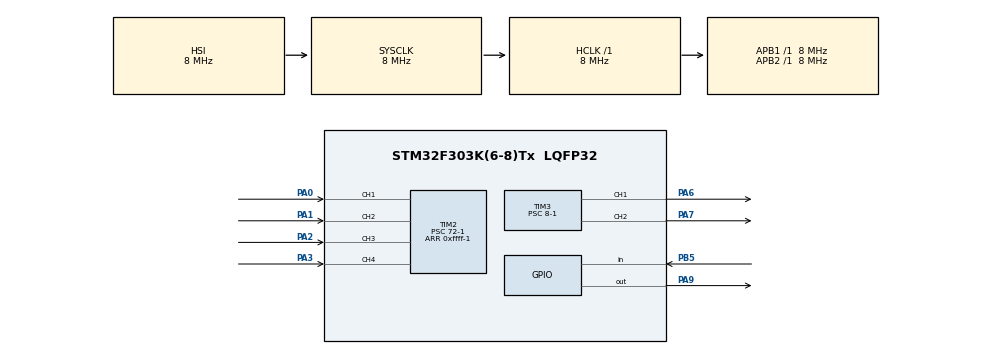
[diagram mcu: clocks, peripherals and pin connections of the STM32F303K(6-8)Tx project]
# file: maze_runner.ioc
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Mcu.Family=STM32F3
Mcu.Name=STM32F303K(6-8)Tx
Mcu.Package=LQFP32
NVIC.PriorityGroup=NVIC_PRIORITYGROUP_4
NVIC.TIM2_IRQn=true\:0\:0\:false\:false\:true\:true\:true\:true
PA0.Signal=S_TIM2_CH1_ETR
PA1.Signal=S_TIM2_CH2
PA2.Signal=S_TIM2_CH3
PA3.Signal=S_TIM2_CH4
PA6.Signal=S_TIM3_CH1
PA7.Signal=S_TIM3_CH2
PA9.Signal=GPIO_Output
PB5.GPIO_PuPd=GPIO_PULLUP
PB5.Signal=GPIO_Input
ProjectManager.HeapSize=0x200
ProjectManager.StackSize=0x400
ProjectManager.TargetToolchain=STM32CubeIDE
RCC.AHBFreq_Value=8000000
RCC.APB1Freq_Value=8000000
RCC.APB2Freq_Value=8000000
RCC.CortexFreq_Value=8000000
RCC.HSE_VALUE=8000000
RCC.HSI_VALUE=8000000
RCC.SYSCLKFreq_VALUE=8000000
SH.S_TIM2_CH1_ETR.0=TIM2_CH1,Input_Capture1_from_TI1
SH.S_TIM2_CH2.0=TIM2_CH2,Input_Capture2_from_TI2
SH.S_TIM2_CH3.0=TIM2_CH3,Input_Capture3_from_TI3
SH.S_TIM2_CH4.0=TIM2_CH4,Input_Capture4_from_TI4
SH.S_TIM3_CH1.0=TIM3_CH1,PWM Generation1 CH1
SH.S_TIM3_CH2.0=TIM3_CH2,PWM Generation2 CH2
TIM2.Channel-Input_Capture1_from_TI1=TIM_CHANNEL_1
TIM2.Channel-Input_Capture2_from_TI2=TIM_CHANNEL_2
TIM2.Channel-Input_Capture3_from_TI3=TIM_CHANNEL_3
TIM2.Channel-Input_Capture4_from_TI4=TIM_CHANNEL_4
TIM2.Period=0xffff-1
TIM2.Prescaler=72-1
TIM3.Channel-PWM\ Generation1\ CH1=TIM_CHANNEL_1
TIM3.Channel-PWM\ Generation2\ CH2=TIM_CHANNEL_2
TIM3.Period=20000-1
TIM3.Prescaler=8-1
TIM3.Pulse-PWM\ Generation1\ CH1=1500-1
TIM3.Pulse-PWM\ Generation2\ CH2=1500-1
VP_TIM3_VS_ClockSourceINT.Mode=Internal
board=custom

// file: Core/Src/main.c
/* USER CODE BEGIN Header */
/**
  ******************************************************************************
  * @file           : main.c
  * @brief          : Main program body
  ******************************************************************************
  * @attention
  *
  * <h2><center>&copy; Copyright (c) 2020 STMicroelectronics.
  * All rights reserved.</center></h2>
  *
  * This software component is licensed by ST under BSD 3-Clause license,
  * the "License"; You may not use this file except in compliance with the
  * License. You may obtain a copy of the License at:
  *                        opensource.org/licenses/BSD-3-Clause
  *
  ******************************************************************************
  */
/* USER CODE END Header */
#include "main.h"
#include "tim.h"
#include "gpio.h"
#include "hcsr04.h"
#include "PCR_servo.h"
#include <stdio.h>
#include <stdlib.h>

int k = 0, before = 0, state = 0;
int i1 = 0, i2 = 0, i3 = 0, i4 = 0;
float d1=1000, d2=1000, d3=1000, d4=1000;
int p1 = 0, p2 = 0, p3 = 0, jp1 = 0, j = 0;

void SystemClock_Config(void);
int validate(int distance, float *sensor, int *current_status, int count);
EDGE_TYPE edgeDetect(uint8_t pin_state, uint8_t samples);

/* USER CODE BEGIN 0 */

// Let's write the callback function

/* USER CODE END 0 */

int main(void)
{

  /* MCU Configuration--------------------------------------------------------*/

  /* Reset of all peripherals, Initializes the Flash interface and the Systick. */
  HAL_Init();

  /* Configure the system clock */
  SystemClock_Config();

  /* Initialize all configured peripherals */
  MX_GPIO_Init();
  MX_TIM3_Init();
  MX_TIM2_Init();
  /* USER CODE BEGIN 2 */
  HAL_TIM_Base_Start(&htim3);
  HAL_TIM_PWM_Start(&htim3, TIM_CHANNEL_1);
  HAL_TIM_PWM_Start(&htim3, TIM_CHANNEL_2);

  HAL_TIM_IC_Start_IT(&htim2, TIM_CHANNEL_1);
  HAL_TIM_IC_Start_IT(&htim2, TIM_CHANNEL_2);
  HAL_TIM_IC_Start_IT(&htim2, TIM_CHANNEL_3);
  HAL_TIM_IC_Start_IT(&htim2, TIM_CHANNEL_4);

  while (1)
  {
	  if (edgeDetect(!HAL_GPIO_ReadPin(GPIOB, GPIO_PIN_5), 3) == RISE) {
		  if (state == 1) state = 0;
	  	  else state = 1;
	      switch (state) {
	      case 1:
	    	  PCR_go_forward();
	    	  break;
	  	  case 0:
	  		  PCR_stand_still();
	  		  break;
	  	  }
	  }
	   before = !HAL_GPIO_ReadPin(GPIOB, GPIO_PIN_5);

	   if (state == 1){
		   j += 1;
		   if (j > 5){
			   j = 0;
			   if (jp1 < 5 && HCSR04_Read2() <= 20){
				   p1 = 0;
				   HAL_Delay(60);
				   if (HCSR04_Read3() > 20){
					   PCR_go_forward();
				   }
				   HAL_Delay(60);
			   } else if (jp1 < 5){
				   p1 = 0;
				   HAL_Delay(60);
				   PCR_go_forward();
			   }
		   }

		   d3 = HCSR04_Read3();

		   if (validate(25, &d3, &i3, 5) == 1){ //front
			   PCR_stand_still();
			   HAL_Delay(60);
			   d1 = HCSR04_Read1();
			   if (validate(20, &d1, &i1, 5) == 1){ //right
				   PCR_stand_still();
				   HAL_Delay(60);
				   d4 = HCSR04_Read4();
				   if (validate(20, &d4, &i4, 5) == 1){ //left
					   PCR_stand_still();
					   HAL_Delay(60);
					   d2 = HCSR04_Read2();
					   if (validate(20, &d2, &i2, 5) == 1){ //back
						   PCR_stand_still();
					   } else{
						   p3 += 1;
					   }
					   if (p3 >= 5){
						   PCR_go_backwards();
						   HAL_Delay(2000);
						   PCR_right_arc(0);
						   HAL_Delay(2000);
						   PCR_go_forward();
						   i1 = 0; i3 = 0; p1 = 0; p2 = 0; p3 = 0; i2 = 0; i4 = 0;
					   } //back end
				   } else{
					   p2 += 1;
				   }
				   if (p2 >= 5){
					   PCR_left_arc(0);
					   HAL_Delay(2000);
					   PCR_go_forward();
					   i1 = 0; i3 = 0; p1 = 0; p2 = 0; p3 = 0; i2 = 0; i4 = 0;
				   } //left end
			   } else{
				   p1 += 1;
			   }
			   if (p1 >= 5){
				   PCR_right_arc(0);
				   HAL_Delay(2000);
				   PCR_go_forward();
				   i1 = 0; i3 = 0; p1 = 0; p2 = 0; p3 = 0; i2 = 0; i4 = 0;
			   } //right end
		   } //front end
		   jp1 = p1;
		   HAL_Delay(60);

		   if (i3 == 0){
			   d1 = HCSR04_Read1();
			   if (validate(10, &d1, &i1, 2) == 1){ //right II
				   PCR_left_arc(1);
			   }
			   HAL_Delay(60);

			   d4 = HCSR04_Read4();
			   if (validate(10, &d4, &i4, 2) == 1){ //left II
				   PCR_right_arc(1);
			   }
			   HAL_Delay(60);
		   }
	   }

  }
  /* USER CODE END 3 */
}

int validate(int distance, float *sensor, int *current_status, int count){ //sensors_front=3, sensor_back=2, sensor_right=1, sensor_left=4
	if (*sensor <= distance){
		*current_status += 1;
	} else{
		*current_status = 0;
	}
	if (*current_status >= count-1){
//		*current_status = 0;
		return 1;
	}
	return 0;
}

EDGE_TYPE edgeDetect(uint8_t pin_state, uint8_t samples){
	if (pin_state == 1 && before == 0 && k == 0){
		k = k+1;
	}
	if (pin_state == 1 && before == 1){
		 k = k+1;
	}
	if (k == samples){
		return RISE;
	}
	if (pin_state == 0){
		k = 0;
		before = 0;
		return NONE;
	}
	return NONE;
}

void SystemClock_Config(void)
{
  RCC_OscInitTypeDef RCC_OscInitStruct = {0};
  RCC_ClkInitTypeDef RCC_ClkInitStruct = {0};

  /** Initializes the RCC Oscillators according to the specified parameters
  * in the RCC_OscInitTypeDef structure.
  */
  RCC_OscInitStruct.OscillatorType = RCC_OSCILLATORTYPE_HSI;
  RCC_OscInitStruct.HSIState = RCC_HSI_ON;
  RCC_OscInitStruct.HSICalibrationValue = RCC_HSICALIBRATION_DEFAULT;
  RCC_OscInitStruct.PLL.PLLState = RCC_PLL_NONE;
  if (HAL_RCC_OscConfig(&RCC_OscInitStruct) != HAL_OK)
  {
    Error_Handler();
  }

  /** Initializes the CPU, AHB and APB buses clocks
  */
  RCC_ClkInitStruct.ClockType = RCC_CLOCKTYPE_HCLK|RCC_CLOCKTYPE_SYSCLK
                              |RCC_CLOCKTYPE_PCLK1|RCC_CLOCKTYPE_PCLK2;
  RCC_ClkInitStruct.SYSCLKSource = RCC_SYSCLKSOURCE_HSI;
  RCC_ClkInitStruct.AHBCLKDivider = RCC_SYSCLK_DIV1;
  RCC_ClkInitStruct.APB1CLKDivider = RCC_HCLK_DIV1;
  RCC_ClkInitStruct.APB2CLKDivider = RCC_HCLK_DIV1;

  if (HAL_RCC_ClockConfig(&RCC_ClkInitStruct, FLASH_LATENCY_0) != HAL_OK)
  {
    Error_Handler();
  }
}

void Error_Handler(void)
{
}
